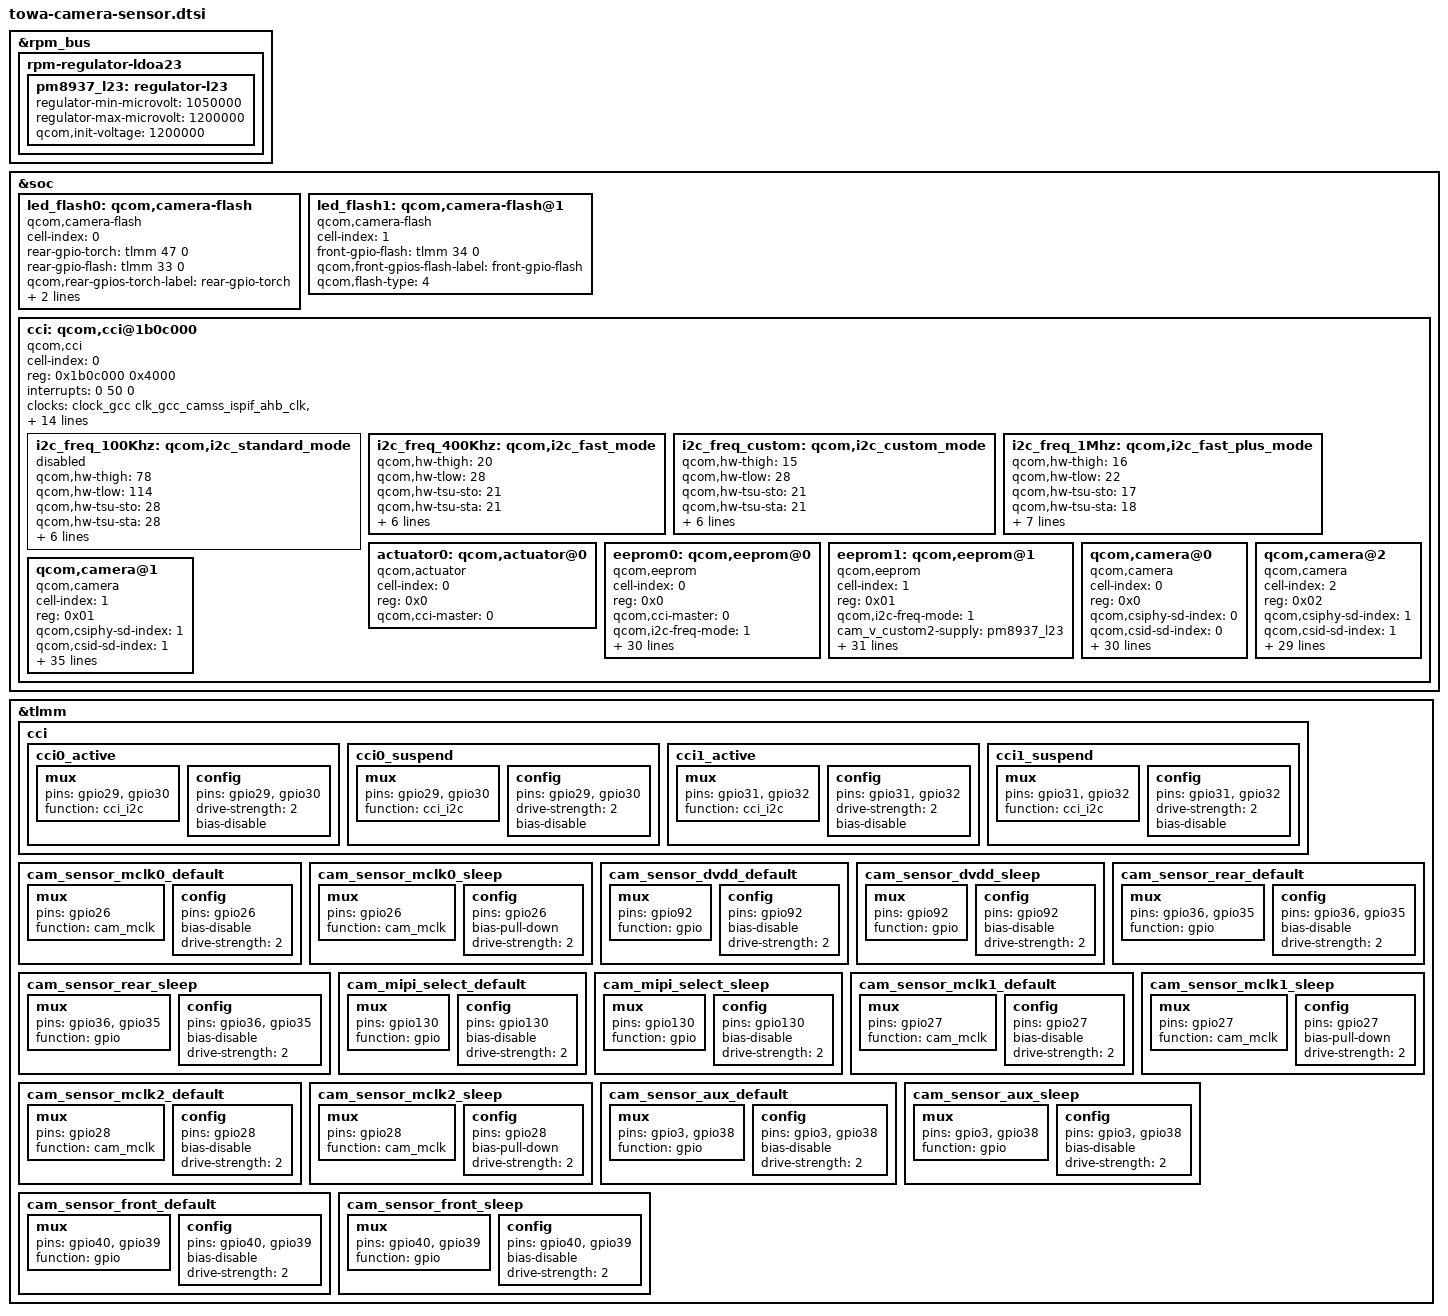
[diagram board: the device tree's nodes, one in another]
/*
 * Copyright (c) 2015-2016, The Linux Foundation. All rights reserved.
 *
 a This program is free software; you can redistribute it and/or modify
 * it under the terms of the GNU General Public License version 2 and
 * only version 2 as published by the Free Software Foundation.
 *
 * This program is distributed in the hope that it will be useful,
 * but WITHOUT ANY WARRANTY; without even the implied warranty of
 * MERCHANTABILITY or FITNESS FOR A PARTICULAR PURPOSE.  See the
 * GNU General Public License for more details.
 */

&rpm_bus {
	rpm-regulator-ldoa23 {
		status = "okay";
		pm8937_l23: regulator-l23 {
			regulator-min-microvolt = <1050000>;
			regulator-max-microvolt = <1200000>;
			qcom,init-voltage = <1200000>;
			status = "okay";
		};
	};
};

&soc {
	led_flash0: qcom,camera-flash {
		cell-index = <0>;
		compatible = "qcom,camera-flash";
		rear-gpio-torch = <&tlmm 47 0>;
		rear-gpio-flash = <&tlmm 33 0>;
		qcom,rear-gpios-torch-label = "rear-gpio-torch";
		qcom,rear-gpios-flash-label = "rear-gpio-flash";
		qcom,flash-type = <5>;
	};
	
	led_flash1: qcom,camera-flash@1 {
		cell-index = <1>;
		compatible = "qcom,camera-flash";
		/*front-gpio-torch = <&tlmm 34 0>;*/
		front-gpio-flash = <&tlmm 34 0>;
		/*qcom,front-gpios-torch-label = "front-gpio-torch";*/
		qcom,front-gpios-flash-label = "front-gpio-flash";
		qcom,flash-type = <4>;
	};

	cci: qcom,cci@1b0c000 {
		status = "ok";
		cell-index = <0>;
		compatible = "qcom,cci";
		reg = <0x1b0c000 0x4000>;
		#address-cells = <1>;
		#size-cells = <0>;
		reg-names = "cci";
		interrupts = <0 50 0>;
		interrupt-names = "cci";
		clocks = <&clock_gcc clk_gcc_camss_ispif_ahb_clk>,
			<&clock_gcc clk_cci_clk_src>,
			<&clock_gcc clk_gcc_camss_cci_ahb_clk>,
			<&clock_gcc clk_gcc_camss_cci_clk>,
			<&clock_gcc clk_gcc_camss_ahb_clk>,
			<&clock_gcc clk_gcc_camss_top_ahb_clk>;
		clock-names = "ispif_ahb_clk", "cci_src_clk",
			"cci_ahb_clk", "camss_cci_clk",
			"camss_ahb_clk", "camss_top_ahb_clk";
		qcom,clock-rates = <61540000 19200000 0 0 0 0>,
				<61540000 37500000 0 0 0 0>;
		pinctrl-names = "cci_default", "cci_suspend";
		pinctrl-0 = <&cci0_active &cci1_active>;
		pinctrl-1 = <&cci0_suspend &cci1_suspend>;
		gpios = <&tlmm 29 0>,
			<&tlmm 30 0>,
			<&tlmm 31 0>,
			<&tlmm 32 0>;
		qcom,gpio-tbl-num = <0 1 2 3>;
		qcom,gpio-tbl-flags = <1 1 1 1>;
		qcom,gpio-tbl-label = "CCI_I2C_DATA0",
							"CCI_I2C_CLK0",
							"CCI_I2C_DATA1",
							"CCI_I2C_CLK1";

		i2c_freq_100Khz: qcom,i2c_standard_mode {
			status = "disabled";
		};
		i2c_freq_400Khz: qcom,i2c_fast_mode {
			status = "disabled";
		};
		i2c_freq_custom: qcom,i2c_custom_mode {
			status = "disabled";
		};

		i2c_freq_1Mhz: qcom,i2c_fast_plus_mode {
			status = "disabled";
		};

	};
};

&i2c_freq_100Khz {
	qcom,hw-thigh = <78>;
	qcom,hw-tlow = <114>;
	qcom,hw-tsu-sto = <28>;
	qcom,hw-tsu-sta = <28>;
	qcom,hw-thd-dat = <10>;
	qcom,hw-thd-sta = <77>;
	qcom,hw-tbuf = <118>;
	qcom,hw-scl-stretch-en = <0>;
	qcom,hw-trdhld = <6>;
	qcom,hw-tsp = <1>;
};

&i2c_freq_400Khz {
	qcom,hw-thigh = <20>;
	qcom,hw-tlow = <28>;
	qcom,hw-tsu-sto = <21>;
	qcom,hw-tsu-sta = <21>;
	qcom,hw-thd-dat = <13>;
	qcom,hw-thd-sta = <18>;
	qcom,hw-tbuf = <32>;
	qcom,hw-scl-stretch-en = <0>;
	qcom,hw-trdhld = <6>;
	qcom,hw-tsp = <3>;
	status = "ok";
};

&i2c_freq_custom {
	qcom,hw-thigh = <15>;
	qcom,hw-tlow = <28>;
	qcom,hw-tsu-sto = <21>;
	qcom,hw-tsu-sta = <21>;
	qcom,hw-thd-dat = <13>;
	qcom,hw-thd-sta = <18>;
	qcom,hw-tbuf = <25>;
	qcom,hw-scl-stretch-en = <1>;
	qcom,hw-trdhld = <6>;
	qcom,hw-tsp = <3>;
	status = "ok";
};

&i2c_freq_1Mhz {
	qcom,hw-thigh = <16>;
	qcom,hw-tlow = <22>;
	qcom,hw-tsu-sto = <17>;
	qcom,hw-tsu-sta = <18>;
	qcom,hw-thd-dat = <16>;
	qcom,hw-thd-sta = <15>;
	qcom,hw-tbuf = <19>;
	qcom,hw-scl-stretch-en = <1>;
	qcom,hw-trdhld = <3>;
	qcom,hw-tsp = <3>;
	qcom,cci-clk-src = <37500000>;
	status = "ok";
};

&tlmm {
    cci {
	cci0_active: cci0_active {
		/* cci0 active state */
		mux {
			/* CLK, DATA */
			pins = "gpio29", "gpio30";
			function = "cci_i2c";
		};

		config {
			pins = "gpio29", "gpio30";
			drive-strength = <2>; /* 2 MA */
			bias-disable; /* No PULL */
		};
	};

	cci0_suspend: cci0_suspend {
		/* cci0 suspended state */
		mux {
			/* CLK, DATA */
			pins = "gpio29", "gpio30";
			function = "cci_i2c";
		};

		config {
			pins = "gpio29", "gpio30";
			drive-strength = <2>; /* 2 MA */
			bias-disable; /* No PULL */
		};
	};

	cci1_active: cci1_active {
		/* cci1 active state */
		mux {
			/* DATA CLK */
			pins = "gpio31", "gpio32";
			function = "cci_i2c";
		};

		config {
			pins = "gpio31", "gpio32";
			drive-strength = <2>; /* 2 MA */
			bias-disable; /* No PULL */
		};
	};

	cci1_suspend: cci1_suspend {
		/* cci1 suspended state */
		mux {
			/* DATA CLK */
			pins = "gpio31", "gpio32";
			function = "cci_i2c";
		};

		config {
			pins = "gpio31", "gpio32";
			drive-strength = <2>; /* 2 MA */
			bias-disable; /* No PULL */
		};
	};
    };
	cam_sensor_mclk0_default: cam_sensor_mclk0_default {
			/* MCLK0 */
			mux {
				/* CLK, DATA */
				pins = "gpio26";
				function = "cam_mclk";
			};

			config {
				pins = "gpio26";
				bias-disable; /* No PULL */
				drive-strength = <8>; /* 8 MA */
			};
		};

		cam_sensor_mclk0_sleep: cam_sensor_mclk0_sleep {
			/* MCLK0 */
			mux {
				/* CLK, DATA */
				pins = "gpio26";
				function = "cam_mclk";
			};

			config {
				pins = "gpio26";
				bias-pull-down; /* PULL DOWN */
				drive-strength = <8>; /* 8 MA */
			};
		};

		cam_sensor_dvdd_default: cam_sensor_dvdd_default {
			/*DVDD */
			mux {
				pins = "gpio92";
				function = "gpio";
			};

			config {
				pins = "gpio92";
				bias-disable; /* No PULL */
				drive-strength = <2>; /* 2 MA */
			};
		};

		cam_sensor_dvdd_sleep: cam_sensor_dvdd_sleep {
			/*DVDD */
			mux {
				pins = "gpio92";
				function = "gpio";
			};

			config {
				pins = "gpio92";
				bias-disable; /* No PULL */
				drive-strength = <2>; /* 2 MA */
			};
		};

		cam_sensor_rear_default: cam_sensor_rear_default {
			/*RESET,STANDBY*/
			mux {
				pins = "gpio36", "gpio35";
				function = "gpio";
			};

			config {
				pins = "gpio36", "gpio35";
				bias-disable; /* No PULL */
				drive-strength = <2>; /* 2 MA */
			};
		};

		cam_sensor_rear_sleep: cam_sensor_rear_sleep {
			/*RESET,STANDBY*/
			mux {
				pins = "gpio36", "gpio35";
				function = "gpio";
			};

			config {
				pins = "gpio36", "gpio35";
				bias-disable; /* No PULL */
				drive-strength = <2>; /* 2 MA */
			};
		};

		cam_mipi_select_default: cam_mipi_select_default{
			/* mipi select*/
			mux {
				pins = "gpio130";
				function = "gpio";
			};

			config {
				pins = "gpio130";
				bias-disable; /* No PULL */
				drive-strength = <2>; /* 2 MA */
			};
		};

		cam_mipi_select_sleep: cam_mipi_select_sleep {
			/* mipi select */
			mux {
				pins = "gpio130";
				function = "gpio";
			};

			config {
				pins = "gpio130";
				bias-disable; /* No PULL */
				drive-strength = <2>; /* 2 MA */
			};
		};

		cam_sensor_mclk0_default: cam_sensor_mclk0_default {
			/* MCLK0 */
			mux {
				/* CLK, DATA */
				pins = "gpio26";
				function = "cam_mclk";
			};

			config {
				pins = "gpio26";
				bias-disable; /* No PULL */
				drive-strength = <2>; /* 2 MA */
			};
		};
		cam_sensor_mclk0_sleep: cam_sensor_mclk0_sleep {
			/* MCLK0 */
			mux {
				/* CLK, DATA */
				pins = "gpio26";
				function = "cam_mclk";
			};

			config {
				pins = "gpio26";
				bias-pull-down; /* PULL DOWN */
				drive-strength = <2>; /* 2 MA */
			};
		};

		cam_sensor_mclk1_default: cam_sensor_mclk1_default {
			/* MCLK1 */
			mux {
				/* CLK, DATA */
				pins = "gpio27";
				function = "cam_mclk";
			};

			config {
				pins = "gpio27";
				bias-disable; /* No PULL */
				drive-strength = <2>; /* 2 MA */
			};
		};
		cam_sensor_mclk1_sleep: cam_sensor_mclk1_sleep {
			/* MCLK0 */
			mux {
				/* CLK, DATA */
				pins = "gpio27";
				function = "cam_mclk";
			};

			config {
				pins = "gpio27";
				bias-pull-down; /* PULL DOWN */
				drive-strength = <2>; /* 2 MA */
			};
		};

		cam_sensor_mclk2_default: cam_sensor_mclk2_default {
			/* MCLK2 */
			mux {
				/* CLK, DATA */
				pins = "gpio28";
				function = "cam_mclk";
			};

			config {
				pins = "gpio28";
				bias-disable; /* No PULL */
				drive-strength = <2>; /* 2 MA */
			};
		};

		cam_sensor_mclk2_sleep: cam_sensor_mclk2_sleep {
			/* MCLK2 */
			mux {
				/* CLK, DATA */
				pins = "gpio28";
				function = "cam_mclk";
			};

			config {
				pins = "gpio28";
				bias-pull-down; /* PULL DOWN */
				drive-strength = <2>; /* 2 MA */
			};
		};

		cam_sensor_aux_default: cam_sensor_aux_default {
			/*POWER_DOWN RESET*/
			mux {
				pins = "gpio3", "gpio38";
				function = "gpio";
			};

			config {
				pins = "gpio3", "gpio38";
				bias-disable; /* No PULL */
				drive-strength = <2>; /* 2 MA */
			};
		};

		cam_sensor_aux_sleep: cam_sensor_aux_sleep {
			/*POWER_DOWN RESET*/
			mux {
				pins = "gpio3", "gpio38";
				function = "gpio";
			};

			config {
				pins = "gpio3", "gpio38";
				bias-disable; /* No PULL */
				drive-strength = <2>; /* 2 MA */
			};
		};

		cam_sensor_front_default: cam_sensor_front_default {
			/* RESET,STANDBY,MIPI_SWITCH*/
			mux {
				pins = "gpio40", "gpio39";
				function = "gpio";
			};

			config {
				pins = "gpio40", "gpio39";
				bias-disable; /* No PULL */
				drive-strength = <2>; /* 2 MA */
			};
		};

		cam_sensor_front_sleep: cam_sensor_front_sleep {
			/* RESET,STANDBY,MIPI_SWITCH*/
			mux {
				pins = "gpio40", "gpio39";
				function = "gpio";
			};

			config {
				pins = "gpio40", "gpio39";
				bias-disable; /* No PULL */
				drive-strength = <2>; /* 2 MA */
			};
		};
};

&cci {
	actuator0: qcom,actuator@0 {
		cell-index = <0>;
		reg = <0x0>;
		compatible = "qcom,actuator";
		qcom,cci-master = <0>;
	};

	eeprom0: qcom,eeprom@0 {
		cell-index = <0>;
		reg = <0x0>;
		compatible = "qcom,eeprom";
		qcom,cci-master = <0>;
		qcom,i2c-freq-mode = <1>;
		qcom,num-blocks = <1>;
		qcom,slave-addr = <0xa0>;
		qcom,page0 = <0 0x0100 2 0x01 1 1>;
		qcom,poll0 = <0 0x0 2 0 1 1>;
		qcom,mem0 = <0x2000 0x0000 2 0 1 0>;

		cam_vana-supply = <&pm8937_l22>;
		cam_vio-supply = <&pm8937_l6>;
		cam_vaf-supply = <&pm8937_l17>;
		qcom,cam-vreg-name = "cam_vio", "cam_vana", "cam_vaf";
		qcom,cam-vreg-min-voltage = <1800000 0 2850000>;
		qcom,cam-vreg-max-voltage = <1800000 0 2850000>;
		qcom,cam-vreg-op-mode = <200000 0 100000>;
		pinctrl-names = "cam_default", "cam_suspend";
		pinctrl-0 = <&cam_sensor_mclk0_default
				&cam_sensor_rear_default
				&cam_sensor_dvdd_default>;
		pinctrl-1 = <&cam_sensor_mclk0_sleep
					&cam_sensor_rear_sleep
					&cam_sensor_dvdd_sleep>;
		gpios = <&tlmm 26 0>,
			<&tlmm 36 0>,
			<&tlmm 35 0>,
			<&tlmm 92 0>;
		qcom,gpio-reset = <1>;
		qcom,gpio-standby = <2>;
		qcom,gpio-vdig = <3>;
		qcom,gpio-req-tbl-num = <0 1 2 3>;
		qcom,gpio-req-tbl-flags = <1 0 0 0>;
		qcom,gpio-req-tbl-label = "CAMIF_MCLK0",
			"CAM_RESET0",
			"CAM_STANDBY0",
			"CAM_DVDD0";
		qcom,sensor-position = <0>;
		qcom,sensor-mode = <0>;
		status = "ok";
		clocks = <&clock_gcc clk_mclk0_clk_src>,
				<&clock_gcc clk_gcc_camss_mclk0_clk>;
		clock-names = "cam_src_clk", "cam_clk";
		qcom,clock-rates = <24000000 0>;
	};
	eeprom1: qcom,eeprom@1 {
		cell-index = <1>;
		reg = <0x01>;
		compatible = "qcom,eeprom";
		qcom,i2c-freq-mode = <1>;
		cam_v_custom2-supply= <&pm8937_l23>;
		cam_vdig-supply = <&pm8937_l23>;
		cam_vana-supply = <&pm8937_l22>;
		cam_vio-supply = <&pm8937_l6>;
		qcom,cam-vreg-name = "cam_v_custom2", "cam_vdig", "cam_vio", "cam_vana";
		qcom,cam-vreg-min-voltage = <1050000 1200000 0 2800000>;
		qcom,cam-vreg-max-voltage = <1050000 1200000 0 2800000>;
		qcom,cam-vreg-op-mode = <105000 105000 0 80000>;
		qcom,gpio-no-mux = <0>;
		pinctrl-names = "cam_default", "cam_suspend";
		pinctrl-0 = <&cam_sensor_mclk2_default
				&cam_sensor_front_default
				&cam_mipi_select_default>;
		pinctrl-1 = <&cam_sensor_mclk2_sleep
				&cam_sensor_front_sleep
				&cam_mipi_select_sleep>;
		gpios = <&tlmm 28 0>,
			<&tlmm 40 0>,
			<&tlmm 39 0>,
			<&tlmm 130 0>;
		qcom,gpio-reset = <1>;
		qcom,gpio-standby = <2>;
		/*mipi switch (0:valid)*/
		qcom,gpio-custom1 = <3>;
		qcom,gpio-req-tbl-num = <0 1 2 3>;
		qcom,gpio-req-tbl-flags = <1 0 0 0>;
		qcom,gpio-req-tbl-label = "CAMIF_MCLK1",
					  "CAM_RESET1",
					  "CAM_STANDBY1",
					  "CAM_MIPI_SWITCH1";
		qcom,sensor-position = <1>;
		qcom,sensor-mode = <0>;
		qcom,cci-master = <0>;
		status = "ok";
		clocks = <&clock_gcc clk_mclk2_clk_src>,
			<&clock_gcc clk_gcc_camss_mclk2_clk>;
		clock-names = "cam_src_clk", "cam_clk";
		qcom,clock-rates = <24000000 0>;
	};

	qcom,camera@0 {
		cell-index = <0>;
		compatible = "qcom,camera";
		reg = <0x0>;
		qcom,csiphy-sd-index = <0>;
		qcom,csid-sd-index = <0>;
		qcom,mount-angle = <90>;
		qcom,led-flash-src = <&led_flash0>;
		qcom,eeprom-src = <&eeprom0>;
		qcom,actuator-src = <&actuator0>;
		cam_vana-supply = <&pm8937_l22>;
		cam_vio-supply = <&pm8937_l6>;
		cam_vaf-supply = <&pm8937_l17>;
		qcom,cam-vreg-name = "cam_vio", "cam_vana", "cam_vaf";
		qcom,cam-vreg-min-voltage = <1800000 0 2850000>;
		qcom,cam-vreg-max-voltage = <1800000 0 2850000>;
		qcom,cam-vreg-op-mode = <200000 0 100000>;
		pinctrl-names = "cam_default", "cam_suspend";
		pinctrl-0 = <&cam_sensor_mclk0_default
				&cam_sensor_rear_default
				&cam_sensor_dvdd_default>;
		pinctrl-1 = <&cam_sensor_mclk0_sleep
					&cam_sensor_rear_sleep
					&cam_sensor_dvdd_sleep>;
		gpios = <&tlmm 26 0>,
			<&tlmm 36 0>,
			<&tlmm 35 0>,
			<&tlmm 92 0>;
		qcom,gpio-reset = <1>;
		qcom,gpio-standby = <2>;
		qcom,gpio-vdig = <3>;
		qcom,gpio-req-tbl-num = <0 1 2 3>;
		qcom,gpio-req-tbl-flags = <1 0 0 0>;
		qcom,gpio-req-tbl-label = "CAMIF_MCLK0",
			"CAM_RESET0",
			"CAM_STANDBY0",
			"CAM_DVDD0";
		qcom,sensor-position = <0>;
		qcom,sensor-mode = <0>;
		qcom,cci-master = <0>;
		status = "ok";
		clocks = <&clock_gcc clk_mclk0_clk_src>,
				<&clock_gcc clk_gcc_camss_mclk0_clk>;
		clock-names = "cam_src_clk", "cam_clk";
		qcom,clock-rates = <24000000 0>;
	};

	qcom,camera@2 {
		cell-index = <2>;
		compatible = "qcom,camera";
		reg = <0x02>;
		qcom,csiphy-sd-index = <1>;
		qcom,csid-sd-index = <1>;
		qcom,mount-angle = <270>;
		qcom,led-flash-src = <&led_flash0>;
		cam_vana-supply = <&pm8937_l22>;
		cam_vio-supply = <&pm8937_l6>;
		qcom,cam-vreg-name =  "cam_vio", "cam_vana";
		qcom,cam-vreg-min-voltage = <1800000 2800000>;
		qcom,cam-vreg-max-voltage = <1800000 2800000>;
		qcom,cam-vreg-op-mode = <105000 80000>;

		pinctrl-names = "cam_default", "cam_suspend";
		pinctrl-0 = <&cam_sensor_mclk1_default
				&cam_sensor_aux_default
				&cam_sensor_dvdd_default
				&cam_mipi_select_default>;
		pinctrl-1 = <&cam_sensor_mclk1_sleep
				&cam_sensor_aux_sleep
				&cam_sensor_dvdd_sleep
				&cam_mipi_select_sleep>;
		gpios = <&tlmm 27 0>,
			<&tlmm 3 0>,
			<&tlmm 92 0>,
			<&tlmm 130 0>;
		/*qcom,gpio-reset = <1>;*/
		qcom,gpio-standby = <1>;
		qcom,gpio-vdig = <2>;
		/*mipi switch (1:valid)*/
		qcom,gpio-custom1 = <3>;
		qcom,gpio-req-tbl-num = <0 1 2 3>;
		qcom,gpio-req-tbl-flags = <1 0 0 0>;
		qcom,gpio-req-tbl-label = "CAMIF_MCLK2",
					  "CAM_STANDBY2",
					  "CAM_DVDD2",
					  "CAM_MIPI_SWITCH2";
		qcom,sensor-position = <1>;
		qcom,sensor-mode = <0>;
		qcom,cci-master = <1>;
		clocks = <&clock_gcc clk_mclk1_clk_src>,
			<&clock_gcc clk_gcc_camss_mclk1_clk>;
		clock-names = "cam_src_clk", "cam_clk";
		qcom,clock-rates = <24000000 0>;
	};

	qcom,camera@1 {
		cell-index = <1>;
		compatible = "qcom,camera";
		reg = <0x01>;
		qcom,csiphy-sd-index = <1>;
		qcom,csid-sd-index = <1>;
		qcom,mount-angle = <270>;
		qcom,led-flash-src = <&led_flash1>;
		qcom,eeprom-src = <&eeprom1>;
		cam_v_custom2-supply= <&pm8937_l23>;
		cam_vdig-supply = <&pm8937_l23>;
		cam_vana-supply = <&pm8937_l22>;
		cam_vio-supply = <&pm8937_l6>;
		qcom,cam-vreg-name = "cam_v_custom2","cam_vdig", "cam_vio", "cam_vana";
		qcom,cam-vreg-min-voltage = <1050000 1200000 0 2800000>;
		qcom,cam-vreg-max-voltage = <1050000 1200000 0 2800000>;
		qcom,cam-vreg-op-mode = <105000 105000 0 80000>;
		qcom,gpio-no-mux = <0>;
		pinctrl-names = "cam_default", "cam_suspend";
		pinctrl-0 = <&cam_sensor_mclk2_default
				&cam_sensor_front_default
				&cam_mipi_select_default>;
		pinctrl-1 = <&cam_sensor_mclk2_sleep
				&cam_sensor_front_sleep
				&cam_mipi_select_sleep>;
		gpios = <&tlmm 28 0>,
			<&tlmm 40 0>,
			<&tlmm 39 0>,
			<&tlmm 130 0>;
		qcom,gpio-reset = <1>;
		qcom,gpio-standby = <2>;
		/*mipi switch (0:valid)*/
		qcom,gpio-custom1 = <3>;
		qcom,gpio-req-tbl-num = <0 1 2 3>;
		qcom,gpio-req-tbl-flags = <1 0 0 0>;
		qcom,gpio-req-tbl-label = "CAMIF_MCLK1",
					  "CAM_RESET1",
					  "CAM_STANDBY1",
					  "CAM_MIPI_SWITCH1";
		qcom,sensor-position = <1>;
		qcom,sensor-mode = <0>;
		qcom,cci-master = <0>;
		status = "ok";
		clocks = <&clock_gcc clk_mclk2_clk_src>,
			<&clock_gcc clk_gcc_camss_mclk2_clk>;
		clock-names = "cam_src_clk", "cam_clk";
		qcom,clock-rates = <24000000 0>;
	};
};
